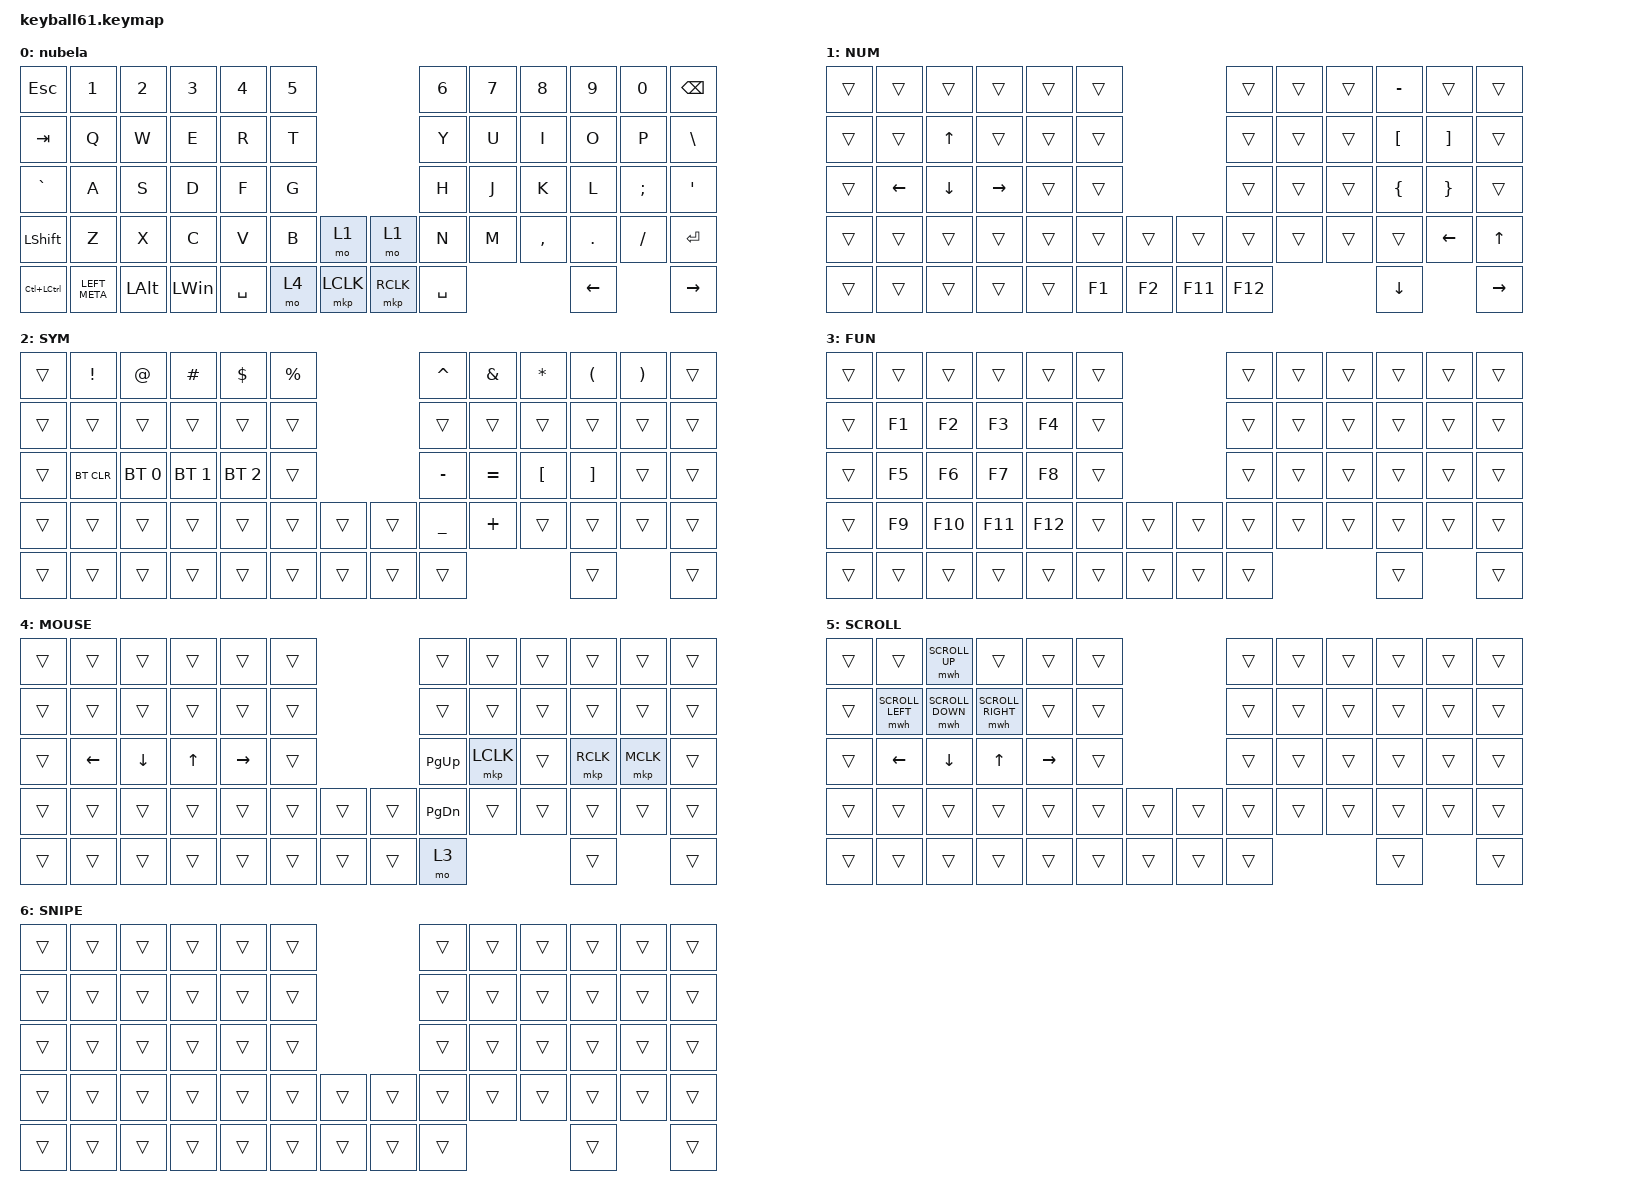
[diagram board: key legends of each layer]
#define DEFAULT 0
#define SYM     1
#define FUN     2
#define MOUSE   3
#define SCROLL  4
#define SNIPE   5

#include <behaviors/mouse_keys.dtsi>
#include <dt-bindings/zmk/mouse.h>
#include <dt-bindings/zmk/mouse.h>
#include <behaviors.dtsi>
#include <dt-bindings/zmk/bt.h>
#include <dt-bindings/zmk/keys.h>
#include <dt-bindings/zmk/mouse.h>

&lt {
    tapping-term-ms = <240>;
    flavor = "balanced";
    quick-tap-ms = <150>;
};

&mt {
    tapping-term-ms = <200>;
    flavor = "tap-preferred";
    quick-tap-ms = <150>;
};

&trackball {
    scroll-layer = <SCROLL>;
    scroll-strength = <30>;
};

/ {
    keymap {
        compatible = "zmk,keymap";

        default_layer {
            label = "nubela";
            bindings = <
&kp ESC         &kp N1         &kp N2        &kp N3        &kp N4     &kp N5                              &kp N6     &kp N7  &kp N8     &kp N9   &kp N0          &kp BSPC
&kp TAB         &kp Q          &kp W         &kp E         &kp R      &kp T                               &kp Y      &kp U   &kp I      &kp O    &kp P           &kp BACKSLASH
&kp GRAVE       &kp A          &kp S         &kp D         &kp F      &kp G                               &kp H      &kp J   &kp K      &kp L    &kp SEMI        &kp SQT
&kp LEFT_SHIFT  &kp Z          &kp X         &kp C         &kp V      &kp B         &mo 1      &mo 1      &kp N      &kp M   &kp COMMA  &kp DOT  &kp FSLH        &kp ENTER
&kp LC(LCTRL)   &kp LEFT_META  &kp LEFT_ALT  &kp LEFT_WIN  &kp SPACE  &mo 4  &mkp LCLK  &mkp RCLK  &kp SPACE                              &kp LEFT_ARROW  &kp RIGHT
            >;
        };

        number_layer {
            bindings = <
&trans  &trans    &trans        &trans     &trans  &trans                   &trans   &trans  &trans  &kp MINUS         &trans             &trans
&trans  &trans    &kp UP_ARROW  &trans     &trans  &trans                   &trans   &trans  &trans  &kp LEFT_BRACKET  &kp RIGHT_BRACKET  &trans
&trans  &kp LEFT  &kp DOWN      &kp RIGHT  &trans  &trans                   &trans   &trans  &trans  &kp LEFT_BRACE    &kp RIGHT_BRACE    &trans
&trans  &trans    &trans        &trans     &trans  &trans  &trans  &trans   &trans   &trans  &trans  &trans            &kp LEFT           &kp UP_ARROW
&trans  &trans    &trans        &trans     &trans  &kp F1  &kp F2  &kp F11  &kp F12                                    &kp DOWN_ARROW     &kp RIGHT
            >;

            label = "NUM";
        };

        symbol_layer {
            label = "SYM";
            bindings = <
&trans  &kp EXCLAMATION  &kp AT_SIGN   &kp HASH      &kp DOLLAR    &kp PERCENT                  &kp CARET       &kp AMPERSAND  &kp ASTERISK      &kp LEFT_PARENTHESIS  &kp RIGHT_PARENTHESIS  &trans
&trans  &trans           &trans        &trans        &trans        &trans                       &trans          &trans         &trans            &trans                &trans                 &trans
&trans  &bt BT_CLR       &bt BT_SEL 0  &bt BT_SEL 1  &bt BT_SEL 2  &trans                       &kp MINUS       &kp EQUAL      &kp LEFT_BRACKET  &kp RIGHT_BRACKET     &trans                 &trans
&trans  &trans           &trans        &trans        &trans        &trans       &trans  &trans  &kp UNDERSCORE  &kp PLUS       &trans            &trans                &trans                 &trans
&trans  &trans           &trans        &trans        &trans        &trans       &trans  &trans  &trans                                                                 &trans                 &trans
            >;
        };

        function_layer {
            label = "FUN";
            bindings = <
&trans  &trans  &trans   &trans   &trans   &trans                  &trans  &trans  &trans  &trans  &trans  &trans
&trans  &kp F1  &kp F2   &kp F3   &kp F4   &trans                  &trans  &trans  &trans  &trans  &trans  &trans
&trans  &kp F5  &kp F6   &kp F7   &kp F8   &trans                  &trans  &trans  &trans  &trans  &trans  &trans
&trans  &kp F9  &kp F10  &kp F11  &kp F12  &trans  &trans  &trans  &trans  &trans  &trans  &trans  &trans  &trans
&trans  &trans  &trans   &trans   &trans   &trans  &trans  &trans  &trans                          &trans  &trans
            >;
        };

        mouse_layer {
            label = "MOUSE";
            bindings = <
&trans  &trans    &trans    &trans  &trans     &trans                  &trans         &trans     &trans  &trans     &trans     &trans
&trans  &trans    &trans    &trans  &trans     &trans                  &trans         &trans     &trans  &trans     &trans     &trans
&trans  &kp LEFT  &kp DOWN  &kp UP  &kp RIGHT  &trans                  &kp PAGE_UP    &mkp LCLK  &trans  &mkp RCLK  &mkp MCLK  &trans
&trans  &trans    &trans    &trans  &trans     &trans  &trans  &trans  &kp PAGE_DOWN  &trans     &trans  &trans     &trans     &trans
&trans  &trans    &trans    &trans  &trans     &trans  &trans  &trans  &mo 3                                        &trans     &trans
            >;
        };

        scroll_layer {
            label = "SCROLL";
            bindings = <
&trans  &trans            &mwh <SCROLL_UP>    &trans              &trans          &trans                             &trans  &trans  &trans  &trans  &trans  &trans
&trans  &mwh <SCROLL_LEFT>  &mwh <SCROLL_DOWN>  &mwh <SCROLL_RIGHT>  &trans          &trans                             &trans  &trans  &trans  &trans  &trans  &trans
&trans  &kp LEFT         &kp DOWN           &kp UP            &kp RIGHT      &trans                             &trans  &trans  &trans  &trans  &trans  &trans
&trans  &trans            &trans             &trans              &trans          &trans        &trans  &trans  &trans  &trans  &trans  &trans  &trans  &trans
&trans  &trans            &trans             &trans              &trans          &trans        &trans  &trans  &trans                          &trans  &trans
            >;
        };

        snipe_layer {
            label = "SNIPE";
            bindings = <
&trans  &trans  &trans  &trans  &trans  &trans                  &trans  &trans  &trans  &trans  &trans  &trans
&trans  &trans  &trans  &trans  &trans  &trans                  &trans  &trans  &trans  &trans  &trans  &trans
&trans  &trans  &trans  &trans  &trans  &trans                  &trans  &trans  &trans  &trans  &trans  &trans
&trans  &trans  &trans  &trans  &trans  &trans  &trans  &trans  &trans  &trans  &trans  &trans  &trans  &trans
&trans  &trans  &trans  &trans  &trans  &trans  &trans  &trans  &trans                          &trans  &trans
            >;
        };
    };
};
